AUTOSAR XML (schema 4-2-1)
standard types defined: uint8, uint8_DataConstr
package /ComponentTypes
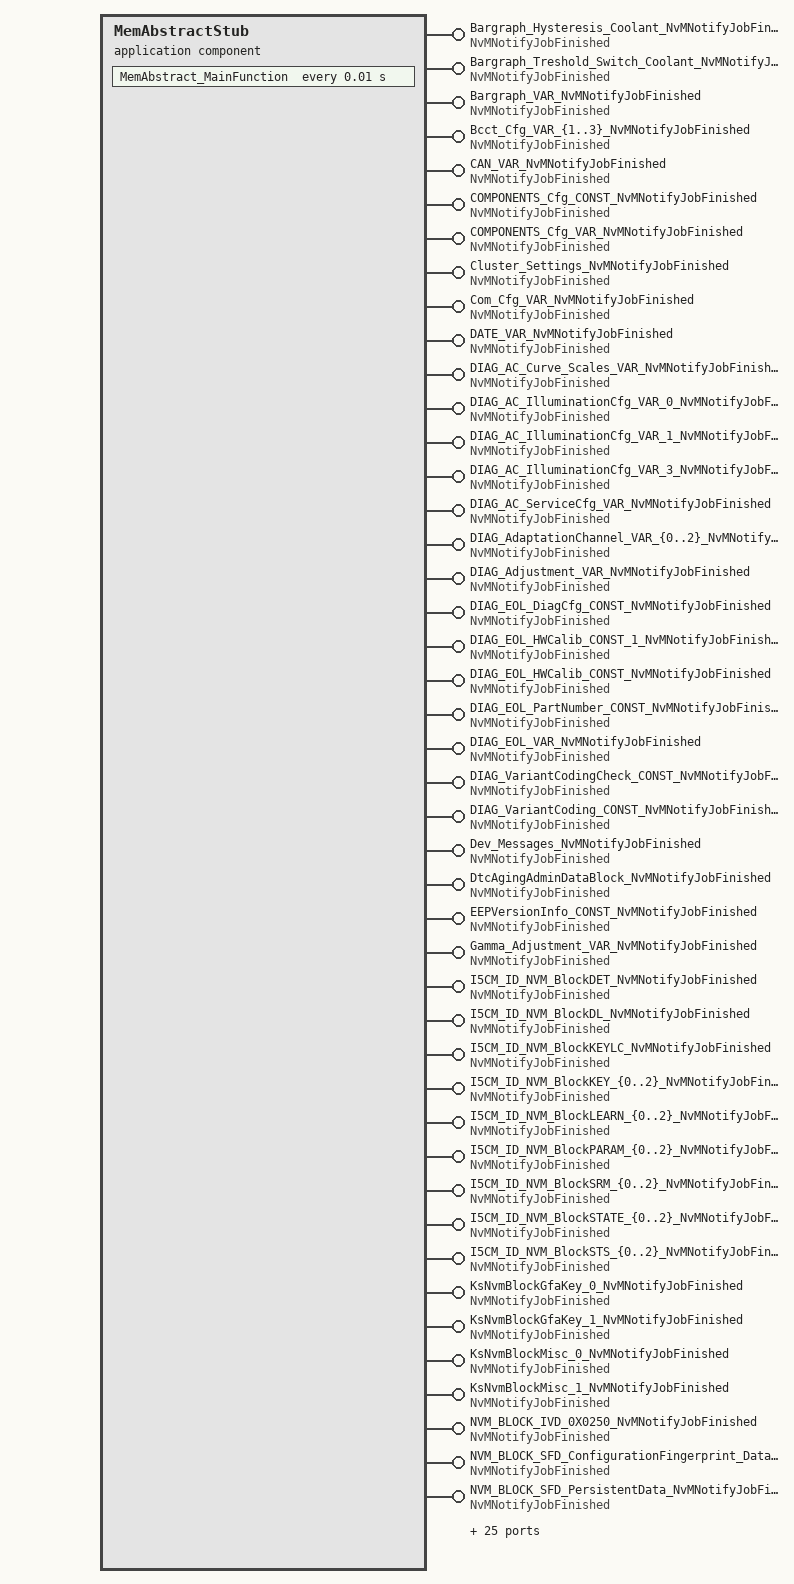
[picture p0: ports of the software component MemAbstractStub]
  application sw component type MemAbstractStub
    94 x provide port, all with server-com-spec{operation=JobFinished, queue-length=1}, provided-interface=NvMNotifyJobFinished:
      Bargraph_Hysteresis_Coolant_NvMNotifyJobFinished
      Bargraph_Treshold_Switch_Coolant_NvMNotifyJobFinished
      Bargraph_VAR_NvMNotifyJobFinished
      Bcct_Cfg_VAR_{1..3}_NvMNotifyJobFinished
      CAN_VAR_NvMNotifyJobFinished
      COMPONENTS_Cfg_CONST_NvMNotifyJobFinished
      COMPONENTS_Cfg_VAR_NvMNotifyJobFinished
      Cluster_Settings_NvMNotifyJobFinished
      Com_Cfg_VAR_NvMNotifyJobFinished
      DATE_VAR_NvMNotifyJobFinished
      DIAG_AC_Curve_Scales_VAR_NvMNotifyJobFinished
      DIAG_AC_IlluminationCfg_VAR_0_NvMNotifyJobFinished
      DIAG_AC_IlluminationCfg_VAR_1_NvMNotifyJobFinished
      DIAG_AC_IlluminationCfg_VAR_3_NvMNotifyJobFinished
      DIAG_AC_ServiceCfg_VAR_NvMNotifyJobFinished
      DIAG_AdaptationChannel_VAR_{0..2}_NvMNotifyJobFinished
      DIAG_Adjustment_VAR_NvMNotifyJobFinished
      DIAG_EOL_DiagCfg_CONST_NvMNotifyJobFinished
      DIAG_EOL_HWCalib_CONST_1_NvMNotifyJobFinished
      DIAG_EOL_HWCalib_CONST_NvMNotifyJobFinished
      DIAG_EOL_PartNumber_CONST_NvMNotifyJobFinished
      DIAG_EOL_VAR_NvMNotifyJobFinished
      DIAG_VariantCodingCheck_CONST_NvMNotifyJobFinished
      DIAG_VariantCoding_CONST_NvMNotifyJobFinished
      Dev_Messages_NvMNotifyJobFinished
      DtcAgingAdminDataBlock_NvMNotifyJobFinished
      EEPVersionInfo_CONST_NvMNotifyJobFinished
      Gamma_Adjustment_VAR_NvMNotifyJobFinished
      I5CM_ID_NVM_BlockDET_NvMNotifyJobFinished
      I5CM_ID_NVM_BlockDL_NvMNotifyJobFinished
      I5CM_ID_NVM_BlockKEYLC_NvMNotifyJobFinished
      I5CM_ID_NVM_BlockKEY_{0..2}_NvMNotifyJobFinished
      I5CM_ID_NVM_BlockLEARN_{0..2}_NvMNotifyJobFinished
      I5CM_ID_NVM_BlockPARAM_{0..2}_NvMNotifyJobFinished
      I5CM_ID_NVM_BlockSRM_{0..2}_NvMNotifyJobFinished
      I5CM_ID_NVM_BlockSTATE_{0..2}_NvMNotifyJobFinished
      I5CM_ID_NVM_BlockSTS_{0..2}_NvMNotifyJobFinished
      KsNvmBlockGfaKey_0_NvMNotifyJobFinished
      KsNvmBlockGfaKey_1_NvMNotifyJobFinished
      KsNvmBlockMisc_0_NvMNotifyJobFinished
      KsNvmBlockMisc_1_NvMNotifyJobFinished
      NVM_BLOCK_IVD_0X0250_NvMNotifyJobFinished
      NVM_BLOCK_SFD_ConfigurationFingerprint_Data_NvMNotifyJobFinished
      NVM_BLOCK_SFD_PersistentData_NvMNotifyJobFinished
      NVM_BLOCK_SFD_PublicKey_NvMNotifyJobFinished
      NvMFblGeneral_NvMNotifyJobFinished
      NvMFblMetaData_NvMNotifyJobFinished
      NvMFblShareDataPartOne_NvMNotifyJobFinished
      NvMFblShareDataPartThree_NvMNotifyJobFinished
      NvMFblShareDataPartTwo_NvMNotifyJobFinished
      NvM_VKMS_NvMNotifyJobFinished
      Nvm_Block_Reserved_1_NvMNotifyJobFinished
      Nvm_Block_Reserved_2_NvMNotifyJobFinished
      Nvm_Block_Reserved_4_NvMNotifyJobFinished
      Odometer_{0..2}_NvMNotifyJobFinished
      OperatingTime_VAR_NvMNotifyJobFinished
      REFUEL_Logger_VAR_NvMNotifyJobFinished
      RGB_Calibration_VAR_NvMNotifyJobFinished
      RPM_Gauge_FIR_Coefficients_NvMNotifyJobFinished
      Recorder_VAR_2_NvMNotifyJobFinished
      Recorder_VAR_NvMNotifyJobFinished
      SAFETY_RECORD_VAR_NvMNotifyJobFinished
      SRV_TKM_ZvCrH_TKM_ZvCrHPimTkKeyInCarNeed_NvMNotifyJobFinished
      SecDiag_NvMNotifyJobFinished
      ServiceKey_VAR_NvMNotifyJobFinished
      Service_History_Data_NvMNotifyJobFinished
      TANK_Variant_CONST_NvMNotifyJobFinished
      USER_PROFILE{0..7}_NvMNotifyJobFinished
      WLTP_Odo_VAR_NvMNotifyJobFinished
    behavior MemAbstractStub_InternalBehavior
      94 x operation invoked event:
        OIT_MemAbstractMdl_NotifyJobEnd_Bargraph_Hysteresis_Coolant_NvMNotifyJobFinished_JobFinished: start-on-event=MemAbstractMdl_NotifyJobEnd_Bargraph_Hysteresis_Coolant, operation=Bargraph_Hysteresis_Coolant_NvMNotifyJobFinished.JobFinished
        OIT_MemAbstractMdl_NotifyJobEnd_Bargraph_Treshold_Switch_Coolant_NvMNotifyJobFinished_JobFinished: start-on-event=MemAbstractMdl_NotifyJobEnd_Bargraph_Treshold_Switch_Coolant, operation=Bargraph_Treshold_Switch_Coolant_NvMNotifyJobFinished.JobFinished
        OIT_MemAbstractMdl_NotifyJobEnd_Bargraph_VAR_NvMNotifyJobFinished_JobFinished: start-on-event=MemAbstractMdl_NotifyJobEnd_Bargraph_VAR, operation=Bargraph_VAR_NvMNotifyJobFinished.JobFinished
        OIT_MemAbstractMdl_NotifyJobEnd_Bcct_Cfg_VAR_{1..3}_NvMNotifyJobFinished_JobFinished: start-on-event=MemAbstractMdl_NotifyJobEnd_Bcct_Cfg_VAR_{1..3}, operation=Bcct_Cfg_VAR_{1..3}_NvMNotifyJobFinished.JobFinished
        OIT_MemAbstractMdl_NotifyJobEnd_CAN_VAR_NvMNotifyJobFinished_JobFinished: start-on-event=MemAbstractMdl_NotifyJobEnd_CAN_VAR, operation=CAN_VAR_NvMNotifyJobFinished.JobFinished
        OIT_MemAbstractMdl_NotifyJobEnd_COMPONENTS_Cfg_CONST_NvMNotifyJobFinished_JobFinished: start-on-event=MemAbstractMdl_NotifyJobEnd_COMPONENTS_Cfg_CONST, operation=COMPONENTS_Cfg_CONST_NvMNotifyJobFinished.JobFinished
        OIT_MemAbstractMdl_NotifyJobEnd_COMPONENTS_Cfg_VAR_NvMNotifyJobFinished_JobFinished: start-on-event=MemAbstractMdl_NotifyJobEnd_COMPONENTS_Cfg_VAR, operation=COMPONENTS_Cfg_VAR_NvMNotifyJobFinished.JobFinished
        OIT_MemAbstractMdl_NotifyJobEnd_Cluster_Settings_NvMNotifyJobFinished_JobFinished: start-on-event=MemAbstractMdl_NotifyJobEnd_Cluster_Settings, operation=Cluster_Settings_NvMNotifyJobFinished.JobFinished
        OIT_MemAbstractMdl_NotifyJobEnd_Com_Cfg_VAR_NvMNotifyJobFinished_JobFinished: start-on-event=MemAbstractMdl_NotifyJobEnd_Com_Cfg_VAR, operation=Com_Cfg_VAR_NvMNotifyJobFinished.JobFinished
        OIT_MemAbstractMdl_NotifyJobEnd_DATE_VAR_NvMNotifyJobFinished_JobFinished: start-on-event=MemAbstractMdl_NotifyJobEnd_DATE_VAR, operation=DATE_VAR_NvMNotifyJobFinished.JobFinished
        OIT_MemAbstractMdl_NotifyJobEnd_DIAG_AC_Curve_Scales_VAR_NvMNotifyJobFinished_JobFinished: start-on-event=MemAbstractMdl_NotifyJobEnd_DIAG_AC_Curve_Scales_VAR, operation=DIAG_AC_Curve_Scales_VAR_NvMNotifyJobFinished.JobFinished
        OIT_MemAbstractMdl_NotifyJobEnd_DIAG_AC_IlluminationCfg_VAR_0_NvMNotifyJobFinished_JobFinished: start-on-event=MemAbstractMdl_NotifyJobEnd_DIAG_AC_IlluminationCfg_VAR_0, operation=DIAG_AC_IlluminationCfg_VAR_0_NvMNotifyJobFinished.JobFinished
        OIT_MemAbstractMdl_NotifyJobEnd_DIAG_AC_IlluminationCfg_VAR_1_NvMNotifyJobFinished_JobFinished: start-on-event=MemAbstractMdl_NotifyJobEnd_DIAG_AC_IlluminationCfg_VAR_1, operation=DIAG_AC_IlluminationCfg_VAR_1_NvMNotifyJobFinished.JobFinished
        OIT_MemAbstractMdl_NotifyJobEnd_DIAG_AC_IlluminationCfg_VAR_3_NvMNotifyJobFinished_JobFinished: start-on-event=MemAbstractMdl_NotifyJobEnd_DIAG_AC_IlluminationCfg_VAR_3, operation=DIAG_AC_IlluminationCfg_VAR_3_NvMNotifyJobFinished.JobFinished
        OIT_MemAbstractMdl_NotifyJobEnd_DIAG_AC_ServiceCfg_VAR_NvMNotifyJobFinished_JobFinished: start-on-event=MemAbstractMdl_NotifyJobEnd_DIAG_AC_ServiceCfg_VAR, operation=DIAG_AC_ServiceCfg_VAR_NvMNotifyJobFinished.JobFinished
        OIT_MemAbstractMdl_NotifyJobEnd_DIAG_AdaptationChannel_VAR_{0..2}_NvMNotifyJobFinished_JobFinished: start-on-event=MemAbstractMdl_NotifyJobEnd_DIAG_AdaptationChannel_VAR_{0..2}, operation=DIAG_AdaptationChannel_VAR_{0..2}_NvMNotifyJobFinished.JobFinished
        OIT_MemAbstractMdl_NotifyJobEnd_DIAG_Adjustment_VAR_NvMNotifyJobFinished_JobFinished: start-on-event=MemAbstractMdl_NotifyJobEnd_DIAG_Adjustment_VAR, operation=DIAG_Adjustment_VAR_NvMNotifyJobFinished.JobFinished
        OIT_MemAbstractMdl_NotifyJobEnd_DIAG_EOL_DiagCfg_CONST_NvMNotifyJobFinished_JobFinished: start-on-event=MemAbstractMdl_NotifyJobEnd_DIAG_EOL_DiagCfg_CONST, operation=DIAG_EOL_DiagCfg_CONST_NvMNotifyJobFinished.JobFinished
        OIT_MemAbstractMdl_NotifyJobEnd_DIAG_EOL_HWCalib_CONST_1_NvMNotifyJobFinished_JobFinished: start-on-event=MemAbstractMdl_NotifyJobEnd_DIAG_EOL_HWCalib_CONST_1, operation=DIAG_EOL_HWCalib_CONST_1_NvMNotifyJobFinished.JobFinished
        OIT_MemAbstractMdl_NotifyJobEnd_DIAG_EOL_HWCalib_CONST_NvMNotifyJobFinished_JobFinished: start-on-event=MemAbstractMdl_NotifyJobEnd_DIAG_EOL_HWCalib_CONST, operation=DIAG_EOL_HWCalib_CONST_NvMNotifyJobFinished.JobFinished
        OIT_MemAbstractMdl_NotifyJobEnd_DIAG_EOL_PartNumber_CONST_NvMNotifyJobFinished_JobFinished: start-on-event=MemAbstractMdl_NotifyJobEnd_DIAG_EOL_PartNumber_CONST, operation=DIAG_EOL_PartNumber_CONST_NvMNotifyJobFinished.JobFinished
        OIT_MemAbstractMdl_NotifyJobEnd_DIAG_EOL_VAR_NvMNotifyJobFinished_JobFinished: start-on-event=MemAbstractMdl_NotifyJobEnd_DIAG_EOL_VAR, operation=DIAG_EOL_VAR_NvMNotifyJobFinished.JobFinished
        OIT_MemAbstractMdl_NotifyJobEnd_DIAG_VariantCodingCheck_CONST_NvMNotifyJobFinished_JobFinished: start-on-event=MemAbstractMdl_NotifyJobEnd_DIAG_VariantCodingCheck_CONST, operation=DIAG_VariantCodingCheck_CONST_NvMNotifyJobFinished.JobFinished
        OIT_MemAbstractMdl_NotifyJobEnd_DIAG_VariantCoding_CONST_NvMNotifyJobFinished_JobFinished: start-on-event=MemAbstractMdl_NotifyJobEnd_DIAG_VariantCoding_CONST, operation=DIAG_VariantCoding_CONST_NvMNotifyJobFinished.JobFinished
        OIT_MemAbstractMdl_NotifyJobEnd_Dev_Messages_NvMNotifyJobFinished_JobFinished: start-on-event=MemAbstractMdl_NotifyJobEnd_Dev_Messages, operation=Dev_Messages_NvMNotifyJobFinished.JobFinished
        OIT_MemAbstractMdl_NotifyJobEnd_DtcAgingAdminDataBlock_NvMNotifyJobFinished_JobFinished: start-on-event=MemAbstractMdl_NotifyJobEnd_DtcAgingAdminDataBlock, operation=DtcAgingAdminDataBlock_NvMNotifyJobFinished.JobFinished
        OIT_MemAbstractMdl_NotifyJobEnd_EEPVersionInfo_CONST_NvMNotifyJobFinished_JobFinished: start-on-event=MemAbstractMdl_NotifyJobEnd_EEPVersionInfo_CONST, operation=EEPVersionInfo_CONST_NvMNotifyJobFinished.JobFinished
        OIT_MemAbstractMdl_NotifyJobEnd_Gamma_Adjustment_VAR_NvMNotifyJobFinished_JobFinished: start-on-event=MemAbstractMdl_NotifyJobEnd_Gamma_Adjustment_VAR, operation=Gamma_Adjustment_VAR_NvMNotifyJobFinished.JobFinished
        OIT_MemAbstractMdl_NotifyJobEnd_I5CM_ID_NVM_BlockDET_NvMNotifyJobFinished_JobFinished: start-on-event=MemAbstractMdl_NotifyJobEnd_I5CM_ID_NVM_BlockDET, operation=I5CM_ID_NVM_BlockDET_NvMNotifyJobFinished.JobFinished
        OIT_MemAbstractMdl_NotifyJobEnd_I5CM_ID_NVM_BlockDL_NvMNotifyJobFinished_JobFinished: start-on-event=MemAbstractMdl_NotifyJobEnd_I5CM_ID_NVM_BlockDL, operation=I5CM_ID_NVM_BlockDL_NvMNotifyJobFinished.JobFinished
        OIT_MemAbstractMdl_NotifyJobEnd_I5CM_ID_NVM_BlockKEYLC_NvMNotifyJobFinished_JobFinished: start-on-event=MemAbstractMdl_NotifyJobEnd_I5CM_ID_NVM_BlockKEYLC, operation=I5CM_ID_NVM_BlockKEYLC_NvMNotifyJobFinished.JobFinished
        OIT_MemAbstractMdl_NotifyJobEnd_I5CM_ID_NVM_BlockKEY_{0..2}_NvMNotifyJobFinished_JobFinished: start-on-event=MemAbstractMdl_NotifyJobEnd_I5CM_ID_NVM_BlockKEY_{0..2}, operation=I5CM_ID_NVM_BlockKEY_{0..2}_NvMNotifyJobFinished.JobFinished
        OIT_MemAbstractMdl_NotifyJobEnd_I5CM_ID_NVM_BlockLEARN_{0..2}_NvMNotifyJobFinished_JobFinished: start-on-event=MemAbstractMdl_NotifyJobEnd_I5CM_ID_NVM_BlockLEARN_{0..2}, operation=I5CM_ID_NVM_BlockLEARN_{0..2}_NvMNotifyJobFinished.JobFinished
        OIT_MemAbstractMdl_NotifyJobEnd_I5CM_ID_NVM_BlockPARAM_{0..2}_NvMNotifyJobFinished_JobFinished: start-on-event=MemAbstractMdl_NotifyJobEnd_I5CM_ID_NVM_BlockPARAM_{0..2}, operation=I5CM_ID_NVM_BlockPARAM_{0..2}_NvMNotifyJobFinished.JobFinished
        OIT_MemAbstractMdl_NotifyJobEnd_I5CM_ID_NVM_BlockSRM_{0..2}_NvMNotifyJobFinished_JobFinished: start-on-event=MemAbstractMdl_NotifyJobEnd_I5CM_ID_NVM_BlockSRM_{0..2}, operation=I5CM_ID_NVM_BlockSRM_{0..2}_NvMNotifyJobFinished.JobFinished
        OIT_MemAbstractMdl_NotifyJobEnd_I5CM_ID_NVM_BlockSTATE_{0..2}_NvMNotifyJobFinished_JobFinished: start-on-event=MemAbstractMdl_NotifyJobEnd_I5CM_ID_NVM_BlockSTATE_{0..2}, operation=I5CM_ID_NVM_BlockSTATE_{0..2}_NvMNotifyJobFinished.JobFinished
        OIT_MemAbstractMdl_NotifyJobEnd_I5CM_ID_NVM_BlockSTS_{0..2}_NvMNotifyJobFinished_JobFinished: start-on-event=MemAbstractMdl_NotifyJobEnd_I5CM_ID_NVM_BlockSTS_{0..2}, operation=I5CM_ID_NVM_BlockSTS_{0..2}_NvMNotifyJobFinished.JobFinished
        OIT_MemAbstractMdl_NotifyJobEnd_KsNvmBlockGfaKey_0_NvMNotifyJobFinished_JobFinished: start-on-event=MemAbstractMdl_NotifyJobEnd_KsNvmBlockGfaKey_0, operation=KsNvmBlockGfaKey_0_NvMNotifyJobFinished.JobFinished
        OIT_MemAbstractMdl_NotifyJobEnd_KsNvmBlockGfaKey_1_NvMNotifyJobFinished_JobFinished: start-on-event=MemAbstractMdl_NotifyJobEnd_KsNvmBlockGfaKey_1, operation=KsNvmBlockGfaKey_1_NvMNotifyJobFinished.JobFinished
        OIT_MemAbstractMdl_NotifyJobEnd_KsNvmBlockMisc_0_NvMNotifyJobFinished_JobFinished: start-on-event=MemAbstractMdl_NotifyJobEnd_KsNvmBlockMisc_0, operation=KsNvmBlockMisc_0_NvMNotifyJobFinished.JobFinished
        OIT_MemAbstractMdl_NotifyJobEnd_KsNvmBlockMisc_1_NvMNotifyJobFinished_JobFinished: start-on-event=MemAbstractMdl_NotifyJobEnd_KsNvmBlockMisc_1, operation=KsNvmBlockMisc_1_NvMNotifyJobFinished.JobFinished
        OIT_MemAbstractMdl_NotifyJobEnd_NVM_BLOCK_IVD_0X0250_NvMNotifyJobFinished_JobFinished: start-on-event=MemAbstractMdl_NotifyJobEnd_NVM_BLOCK_IVD_0X0250, operation=NVM_BLOCK_IVD_0X0250_NvMNotifyJobFinished.JobFinished
        OIT_MemAbstractMdl_NotifyJobEnd_NVM_BLOCK_SFD_ConfigurationFingerprint_Data_NvMNotifyJobFinished_JobFinished: start-on-event=MemAbstractMdl_NotifyJobEnd_NVM_BLOCK_SFD_ConfigurationFingerprint_Data, operation=NVM_BLOCK_SFD_ConfigurationFingerprint_Data_NvMNotifyJobFinished.JobFinished
        OIT_MemAbstractMdl_NotifyJobEnd_NVM_BLOCK_SFD_PersistentData_NvMNotifyJobFinished_JobFinished: start-on-event=MemAbstractMdl_NotifyJobEnd_NVM_BLOCK_SFD_PersistentData, operation=NVM_BLOCK_SFD_PersistentData_NvMNotifyJobFinished.JobFinished
        OIT_MemAbstractMdl_NotifyJobEnd_NVM_BLOCK_SFD_PublicKey_NvMNotifyJobFinished_JobFinished: start-on-event=MemAbstractMdl_NotifyJobEnd_NVM_BLOCK_SFD_PublicKey, operation=NVM_BLOCK_SFD_PublicKey_NvMNotifyJobFinished.JobFinished
        OIT_MemAbstractMdl_NotifyJobEnd_NvMFblGeneral_NvMNotifyJobFinished_JobFinished: start-on-event=MemAbstractMdl_NotifyJobEnd_NvMFblGeneral, operation=NvMFblGeneral_NvMNotifyJobFinished.JobFinished
        OIT_MemAbstractMdl_NotifyJobEnd_NvMFblMetaData_NvMNotifyJobFinished_JobFinished: start-on-event=MemAbstractMdl_NotifyJobEnd_NvMFblMetaData, operation=NvMFblMetaData_NvMNotifyJobFinished.JobFinished
        OIT_MemAbstractMdl_NotifyJobEnd_NvMFblShareDataPartOne_NvMNotifyJobFinished_JobFinished: start-on-event=MemAbstractMdl_NotifyJobEnd_NvMFblShareDataPartOne, operation=NvMFblShareDataPartOne_NvMNotifyJobFinished.JobFinished
        OIT_MemAbstractMdl_NotifyJobEnd_NvMFblShareDataPartThree_NvMNotifyJobFinished_JobFinished: start-on-event=MemAbstractMdl_NotifyJobEnd_NvMFblShareDataPartThree, operation=NvMFblShareDataPartThree_NvMNotifyJobFinished.JobFinished
        OIT_MemAbstractMdl_NotifyJobEnd_NvMFblShareDataPartTwo_NvMNotifyJobFinished_JobFinished: start-on-event=MemAbstractMdl_NotifyJobEnd_NvMFblShareDataPartTwo, operation=NvMFblShareDataPartTwo_NvMNotifyJobFinished.JobFinished
        OIT_MemAbstractMdl_NotifyJobEnd_NvM_VKMS_NvMNotifyJobFinished_JobFinished: start-on-event=MemAbstractMdl_NotifyJobEnd_NvM_VKMS, operation=NvM_VKMS_NvMNotifyJobFinished.JobFinished
        OIT_MemAbstractMdl_NotifyJobEnd_Nvm_Block_Reserved_1_NvMNotifyJobFinished_JobFinished: start-on-event=MemAbstractMdl_NotifyJobEnd_Nvm_Block_Reserved_1, operation=Nvm_Block_Reserved_1_NvMNotifyJobFinished.JobFinished
        OIT_MemAbstractMdl_NotifyJobEnd_Nvm_Block_Reserved_2_NvMNotifyJobFinished_JobFinished: start-on-event=MemAbstractMdl_NotifyJobEnd_Nvm_Block_Reserved_2, operation=Nvm_Block_Reserved_2_NvMNotifyJobFinished.JobFinished
        OIT_MemAbstractMdl_NotifyJobEnd_Nvm_Block_Reserved_4_NvMNotifyJobFinished_JobFinished: start-on-event=MemAbstractMdl_NotifyJobEnd_Nvm_Block_Reserved_4, operation=Nvm_Block_Reserved_4_NvMNotifyJobFinished.JobFinished
        OIT_MemAbstractMdl_NotifyJobEnd_Odometer_{0..2}_NvMNotifyJobFinished_JobFinished: start-on-event=MemAbstractMdl_NotifyJobEnd_Odometer_{0..2}, operation=Odometer_{0..2}_NvMNotifyJobFinished.JobFinished
        OIT_MemAbstractMdl_NotifyJobEnd_OperatingTime_VAR_NvMNotifyJobFinished_JobFinished: start-on-event=MemAbstractMdl_NotifyJobEnd_OperatingTime_VAR, operation=OperatingTime_VAR_NvMNotifyJobFinished.JobFinished
        OIT_MemAbstractMdl_NotifyJobEnd_REFUEL_Logger_VAR_NvMNotifyJobFinished_JobFinished: start-on-event=MemAbstractMdl_NotifyJobEnd_REFUEL_Logger_VAR, operation=REFUEL_Logger_VAR_NvMNotifyJobFinished.JobFinished
        OIT_MemAbstractMdl_NotifyJobEnd_RGB_Calibration_VAR_NvMNotifyJobFinished_JobFinished: start-on-event=MemAbstractMdl_NotifyJobEnd_RGB_Calibration_VAR, operation=RGB_Calibration_VAR_NvMNotifyJobFinished.JobFinished
        OIT_MemAbstractMdl_NotifyJobEnd_RPM_Gauge_FIR_Coefficients_NvMNotifyJobFinished_JobFinished: start-on-event=MemAbstractMdl_NotifyJobEnd_RPM_Gauge_FIR_Coefficients, operation=RPM_Gauge_FIR_Coefficients_NvMNotifyJobFinished.JobFinished
        OIT_MemAbstractMdl_NotifyJobEnd_Recorder_VAR_2_NvMNotifyJobFinished_JobFinished: start-on-event=MemAbstractMdl_NotifyJobEnd_Recorder_VAR_2, operation=Recorder_VAR_2_NvMNotifyJobFinished.JobFinished
        OIT_MemAbstractMdl_NotifyJobEnd_Recorder_VAR_NvMNotifyJobFinished_JobFinished: start-on-event=MemAbstractMdl_NotifyJobEnd_Recorder_VAR, operation=Recorder_VAR_NvMNotifyJobFinished.JobFinished
        OIT_MemAbstractMdl_NotifyJobEnd_SAFETY_RECORD_VAR_NvMNotifyJobFinished_JobFinished: start-on-event=MemAbstractMdl_NotifyJobEnd_SAFETY_RECORD_VAR, operation=SAFETY_RECORD_VAR_NvMNotifyJobFinished.JobFinished
        OIT_MemAbstractMdl_NotifyJobEnd_SRV_TKM_ZvCrH_TKM_ZvCrHPimTkKeyInCarNeed_NvMNotifyJobFinished_JobFinished: start-on-event=MemAbstractMdl_NotifyJobEnd_SRV_TKM_ZvCrH_TKM_ZvCrHPimTkKeyInCarNeed, operation=SRV_TKM_ZvCrH_TKM_ZvCrHPimTkKeyInCarNeed_NvMNotifyJobFinished.JobFinished
        OIT_MemAbstractMdl_NotifyJobEnd_SecDiag_NvMNotifyJobFinished_JobFinished: start-on-event=MemAbstractMdl_NotifyJobEnd_SecDiag, operation=SecDiag_NvMNotifyJobFinished.JobFinished
        OIT_MemAbstractMdl_NotifyJobEnd_ServiceKey_VAR_NvMNotifyJobFinished_JobFinished: start-on-event=MemAbstractMdl_NotifyJobEnd_ServiceKey_VAR, operation=ServiceKey_VAR_NvMNotifyJobFinished.JobFinished
        OIT_MemAbstractMdl_NotifyJobEnd_Service_History_Data_NvMNotifyJobFinished_JobFinished: start-on-event=MemAbstractMdl_NotifyJobEnd_Service_History_Data, operation=Service_History_Data_NvMNotifyJobFinished.JobFinished
        OIT_MemAbstractMdl_NotifyJobEnd_TANK_Variant_CONST_NvMNotifyJobFinished_JobFinished: start-on-event=MemAbstractMdl_NotifyJobEnd_TANK_Variant_CONST, operation=TANK_Variant_CONST_NvMNotifyJobFinished.JobFinished
        OIT_MemAbstractMdl_NotifyJobEnd_USER_PROFILE{0..7}_NvMNotifyJobFinished_JobFinished: start-on-event=MemAbstractMdl_NotifyJobEnd_USER_PROFILE{0..7}, operation=USER_PROFILE{0..7}_NvMNotifyJobFinished.JobFinished
        OIT_MemAbstractMdl_NotifyJobEnd_WLTP_Odo_VAR_NvMNotifyJobFinished_JobFinished: start-on-event=MemAbstractMdl_NotifyJobEnd_WLTP_Odo_VAR, operation=WLTP_Odo_VAR_NvMNotifyJobFinished.JobFinished
      timing event TMT_MemAbstract_MainFunction: start-on-event=MemAbstract_MainFunction, period=0.01
      95 x runnable:
        MemAbstractMdl_NotifyJobEnd_Bargraph_Hysteresis_Coolant
        MemAbstractMdl_NotifyJobEnd_Bargraph_Treshold_Switch_Coolant
        MemAbstractMdl_NotifyJobEnd_Bargraph_VAR
        MemAbstractMdl_NotifyJobEnd_Bcct_Cfg_VAR_{1..3}
        MemAbstractMdl_NotifyJobEnd_CAN_VAR
        MemAbstractMdl_NotifyJobEnd_COMPONENTS_Cfg_CONST
        MemAbstractMdl_NotifyJobEnd_COMPONENTS_Cfg_VAR
        MemAbstractMdl_NotifyJobEnd_Cluster_Settings
        MemAbstractMdl_NotifyJobEnd_Com_Cfg_VAR
        MemAbstractMdl_NotifyJobEnd_DATE_VAR
        MemAbstractMdl_NotifyJobEnd_DIAG_AC_Curve_Scales_VAR
        MemAbstractMdl_NotifyJobEnd_DIAG_AC_IlluminationCfg_VAR_0
        MemAbstractMdl_NotifyJobEnd_DIAG_AC_IlluminationCfg_VAR_1
        MemAbstractMdl_NotifyJobEnd_DIAG_AC_IlluminationCfg_VAR_3
        MemAbstractMdl_NotifyJobEnd_DIAG_AC_ServiceCfg_VAR
        MemAbstractMdl_NotifyJobEnd_DIAG_AdaptationChannel_VAR_{0..2}
        MemAbstractMdl_NotifyJobEnd_DIAG_Adjustment_VAR
        MemAbstractMdl_NotifyJobEnd_DIAG_EOL_DiagCfg_CONST
        MemAbstractMdl_NotifyJobEnd_DIAG_EOL_HWCalib_CONST
        MemAbstractMdl_NotifyJobEnd_DIAG_EOL_HWCalib_CONST_1
        MemAbstractMdl_NotifyJobEnd_DIAG_EOL_PartNumber_CONST
        MemAbstractMdl_NotifyJobEnd_DIAG_EOL_VAR
        MemAbstractMdl_NotifyJobEnd_DIAG_VariantCodingCheck_CONST
        MemAbstractMdl_NotifyJobEnd_DIAG_VariantCoding_CONST
        MemAbstractMdl_NotifyJobEnd_Dev_Messages
        MemAbstractMdl_NotifyJobEnd_DtcAgingAdminDataBlock
        MemAbstractMdl_NotifyJobEnd_EEPVersionInfo_CONST
        MemAbstractMdl_NotifyJobEnd_Gamma_Adjustment_VAR
        MemAbstractMdl_NotifyJobEnd_I5CM_ID_NVM_BlockDET
        MemAbstractMdl_NotifyJobEnd_I5CM_ID_NVM_BlockDL
        MemAbstractMdl_NotifyJobEnd_I5CM_ID_NVM_BlockKEYLC
        MemAbstractMdl_NotifyJobEnd_I5CM_ID_NVM_BlockKEY_{0..2}
        MemAbstractMdl_NotifyJobEnd_I5CM_ID_NVM_BlockLEARN_{0..2}
        MemAbstractMdl_NotifyJobEnd_I5CM_ID_NVM_BlockPARAM_{0..2}
        MemAbstractMdl_NotifyJobEnd_I5CM_ID_NVM_BlockSRM_{0..2}
        MemAbstractMdl_NotifyJobEnd_I5CM_ID_NVM_BlockSTATE_{0..2}
        MemAbstractMdl_NotifyJobEnd_I5CM_ID_NVM_BlockSTS_{0..2}
        MemAbstractMdl_NotifyJobEnd_KsNvmBlockGfaKey_0
        MemAbstractMdl_NotifyJobEnd_KsNvmBlockGfaKey_1
        MemAbstractMdl_NotifyJobEnd_KsNvmBlockMisc_0
        MemAbstractMdl_NotifyJobEnd_KsNvmBlockMisc_1
        MemAbstractMdl_NotifyJobEnd_NVM_BLOCK_IVD_0X0250
        MemAbstractMdl_NotifyJobEnd_NVM_BLOCK_SFD_ConfigurationFingerprint_Data
        MemAbstractMdl_NotifyJobEnd_NVM_BLOCK_SFD_PersistentData
        MemAbstractMdl_NotifyJobEnd_NVM_BLOCK_SFD_PublicKey
        MemAbstractMdl_NotifyJobEnd_NvMFblGeneral
        MemAbstractMdl_NotifyJobEnd_NvMFblMetaData
        MemAbstractMdl_NotifyJobEnd_NvMFblShareDataPartOne
        MemAbstractMdl_NotifyJobEnd_NvMFblShareDataPartThree
        MemAbstractMdl_NotifyJobEnd_NvMFblShareDataPartTwo
        MemAbstractMdl_NotifyJobEnd_NvM_VKMS
        MemAbstractMdl_NotifyJobEnd_Nvm_Block_Reserved_1
        MemAbstractMdl_NotifyJobEnd_Nvm_Block_Reserved_2
        MemAbstractMdl_NotifyJobEnd_Nvm_Block_Reserved_4
        MemAbstractMdl_NotifyJobEnd_Odometer_{0..2}
        MemAbstractMdl_NotifyJobEnd_OperatingTime_VAR
        MemAbstractMdl_NotifyJobEnd_REFUEL_Logger_VAR
        MemAbstractMdl_NotifyJobEnd_RGB_Calibration_VAR
        MemAbstractMdl_NotifyJobEnd_RPM_Gauge_FIR_Coefficients
        MemAbstractMdl_NotifyJobEnd_Recorder_VAR
        MemAbstractMdl_NotifyJobEnd_Recorder_VAR_2
        MemAbstractMdl_NotifyJobEnd_SAFETY_RECORD_VAR
        MemAbstractMdl_NotifyJobEnd_SRV_TKM_ZvCrH_TKM_ZvCrHPimTkKeyInCarNeed
        MemAbstractMdl_NotifyJobEnd_SecDiag
        MemAbstractMdl_NotifyJobEnd_ServiceKey_VAR
        MemAbstractMdl_NotifyJobEnd_Service_History_Data
        MemAbstractMdl_NotifyJobEnd_TANK_Variant_CONST
        MemAbstractMdl_NotifyJobEnd_USER_PROFILE{0..7}
        MemAbstractMdl_NotifyJobEnd_WLTP_Odo_VAR
        MemAbstract_MainFunction
  swc implementation MemAbstractStub_Implementation: behavior=MemAbstractStub_InternalBehavior
    code-descriptors:
      code Default: artifact-descriptors=autosar-engineering-object={short-label=Default, category=SWSRC}
package /Predefined_DEV/ImplementationDataTypes
  impl type NvM_RequestResultType: compu {0=NVM_REQ_OK, 1=NVM_REQ_NOT_OK, 2=NVM_REQ_PENDING, 3=NVM_REQ_INTEGRITY_FAILED, 4=NVM_REQ_BLOCK_SKIPPED, 5=NVM_REQ_NV_INVALIDATED, 6=NVM_REQ_CANCELED, 7=NVM_REQ_REDUNDANCY_FAILED, 8=NVM_REQ_RESTORED_FROM_ROM}, implementation-data-type=uint8
  impl type NvM_ServiceIdType: compu {6=NVM_READ_BLOCK, 7=NVM_WRITE_BLOCK, 8=NVM_RESTORE_BLOCK_DEFAULTS, 9=NVM_ERASE_BLOCK, 11=NVM_INVALIDATE_NV_BLOCK, 12=NVM_READ_ALL}, implementation-data-type=uint8
package /Predefined_DEV/PortInterfaces
  client server interface NvMNotifyJobFinished: is-service=true
    operation JobFinished
      arg ServiceId: type=NvM_ServiceIdType, direction=IN, server-argument-impl-policy=USE-ARGUMENT-TYPE
      arg JobResult: type=NvM_RequestResultType, direction=IN, server-argument-impl-policy=USE-ARGUMENT-TYPE
